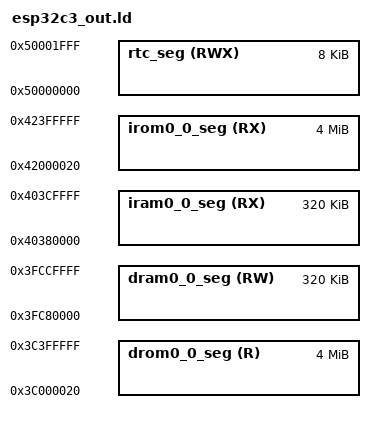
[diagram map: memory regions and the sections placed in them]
/****************************************************************************
 * boards/risc-v/esp32c3/esp32c3-devkit/scripts/esp32c3.template.ld
 *
 * Licensed to the Apache Software Foundation (ASF) under one or more
 * contributor license agreements.  See the NOTICE file distributed with
 * this work for additional information regarding copyright ownership.  The
 * ASF licenses this file to you under the Apache License, Version 2.0 (the
 * "License"); you may not use this file except in compliance with the
 * License.  You may obtain a copy of the License at
 *
 *   http://www.apache.org/licenses/LICENSE-2.0
 *
 * Unless required by applicable law or agreed to in writing, software
 * distributed under the License is distributed on an "AS IS" BASIS, WITHOUT
 * WARRANTIES OR CONDITIONS OF ANY KIND, either express or implied.  See the
 * License for the specific language governing permissions and limitations
 * under the License.
 *
 ****************************************************************************/
/****************************************************************************
 * This file describes the memory layout (memory blocks) as virtual
 * memory addresses.
 *
 * NOTE: That this is not the actual linker script but rather a "template"
 * for the esp32c3_out.ld script.  This template script is passed through
 * the C preprocessor to include selected configuration options.
 *
 ****************************************************************************/
/* config.h -- Autogenerated! Do not edit. */
/* Used to represent the values of tristate options */
/* General Definitions ***********************************/
/* Sanity Checks *****************************************/
/* If the end of RAM is not specified then it is assumed to be
 * the beginning of RAM plus the RAM size.
 */
/* If the end of FLASH is not specified then it is assumed to be
 * the beginning of FLASH plus the FLASH size.
 */
/****************************************************************************
 * boards/risc-v/esp32c3/esp32c3-devkit/scripts/esp32c3_aliases.ld
 *
 * Licensed to the Apache Software Foundation (ASF) under one or more
 * contributor license agreements.  See the NOTICE file distributed with
 * this work for additional information regarding copyright ownership.  The
 * ASF licenses this file to you under the Apache License, Version 2.0 (the
 * "License"); you may not use this file except in compliance with the
 * License.  You may obtain a copy of the License at
 *
 *   http://www.apache.org/licenses/LICENSE-2.0
 *
 * Unless required by applicable law or agreed to in writing, software
 * distributed under the License is distributed on an "AS IS" BASIS, WITHOUT
 * WARRANTIES OR CONDITIONS OF ANY KIND, either express or implied.  See the
 * License for the specific language governing permissions and limitations
 * under the License.
 *
 ****************************************************************************/
/* ICache size is fixed to 16KB on ESP32-C3 */
/* 2nd stage bootloader iram_loader_seg start address */
MEMORY
{
  /* Below values assume the flash cache is on, and have the blocks this
   * uses subtracted from the length of the various regions. The 'data access
   * port' dram/drom regions map to the same iram/irom regions but are
   * connected to the data port of the CPU and e.g. allow bytewise access.
   */
  iram0_0_seg (RX) : org = (0x4037c000 + 0x4000), len = 0x403d0000 - (0x4037c000 - 0x3fc7c000) - (0x3fc7c000 + 0x4000)
  /* Flash mapped instruction data. */
  /* The 0x20 offset is a convenience for the app binary image generation.
   * Flash cache has 64KB pages. The .bin file which is flashed to the chip
   * has a 0x18 byte file header, and each segment has a 0x08 byte segment
   * header. Setting this offset makes it simple to meet the flash cache MMU's
   * constraint that (paddr % 64KB == vaddr % 64KB).
   */
  irom0_0_seg (RX) : org = 0x42000020, len = 0x400000 - 0x20
  /* Shared data RAM, excluding memory reserved for ROM bss/data/stack. */
  dram0_0_seg (RW) : org = (0x3fc7c000 + 0x4000), len = 0x403d0000 - (0x4037c000 - 0x3fc7c000) - (0x3fc7c000 + 0x4000)
  /* Flash mapped constant data */
  /* The 0x20 offset is a convenience for the app binary image generation.
   * Flash cache has 64KB pages. The .bin file which is flashed to the chip
   * has a 0x18 byte file header, and each segment has a 0x08 byte segment
   * header. Setting this offset makes it simple to meet the flash cache MMU's
   * constraint that (paddr % 64KB == vaddr % 64KB).
   */
  drom0_0_seg (R) : org = 0x3c000020, len = 0x400000 - 0x20
  /* RTC fast memory. Persists over deep sleep. */
  rtc_seg(RWX) : org = 0x50000000, len = 0x2000
}
  REGION_ALIAS("default_rodata_seg", drom0_0_seg);
  REGION_ALIAS("default_code_seg", irom0_0_seg);
/* Mark the end of the RTC heap (top of the RTC region) */
_ertcheap = 0x50001fff;
